# PRU_ICSSG0_PR1_MDIO_V1P7_MDIO register map
Vendor: Texas Instruments
Peripheral module from a debugger description file (folder am243x).
Registers are 32-bit, access not given, reset 0x0 unless marked. A register's access mark holds for its fields unless they carry their own. Offsets are as the file gives them; lines under a group give offsets from that group; [hi:lo] are bit positions; {n}, {i} and the like mark numbered series; 'fields as' and 'values as' point back to an identical list; <NAME> marks a mode.

## PRU_ICSSG0_PR1_MDIO_V1P7_MDIO
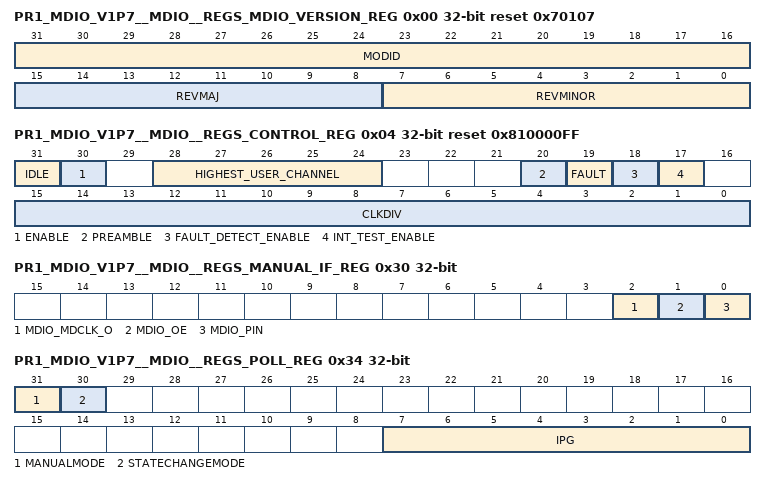
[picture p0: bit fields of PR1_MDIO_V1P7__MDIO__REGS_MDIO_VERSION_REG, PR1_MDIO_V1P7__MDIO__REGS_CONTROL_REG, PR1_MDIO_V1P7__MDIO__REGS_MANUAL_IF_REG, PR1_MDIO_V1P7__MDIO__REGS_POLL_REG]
0x00 PR1_MDIO_V1P7__MDIO__REGS_MDIO_VERSION_REG ro reset 0x70107 — version_reg
  [31:16] MODID — Module ID
  [15:8] REVMAJ — Major revision value
  [7:0] REVMINOR — Minor revision value
0x04 PR1_MDIO_V1P7__MDIO__REGS_CONTROL_REG reset 0x810000FF — control_reg
  [31] IDLE ro — MDIO state machine idle
  [30] ENABLE rw — Enable control
  [28:24] HIGHEST_USER_CHANNEL ro
  [20] PREAMBLE rw — Preamble disable
  [19] FAULT — Fault indicator (access R/W1TC)
  [18] FAULT_DETECT_ENABLE rw
  [17] INT_TEST_ENABLE rw — Interrupt test enable
  [15:0] CLKDIV rw — Clock divider
0x08 PR1_MDIO_V1P7__MDIO__REGS_ALIVE_REG — alive_reg
  [31:0] ALIVE — MDIO alive (access R/W1TC)
0x0C PR1_MDIO_V1P7__MDIO__REGS_LINK_REG ro — link_reg
  [31:0] LINK — MDIO link state
0x10 PR1_MDIO_V1P7__MDIO__REGS_LINK_INT_RAW_REG — link_int_raw_reg
  [1:0] LINKINTRAW — MDIO link change event raw value (access R/W1TC)
0x14 PR1_MDIO_V1P7__MDIO__REGS_LINK_INT_MASKED_REG — link_int_masked_reg
  [1:0] LINKINTMASKED — MDIO link change interrupt masked value (access R/W1TC)
0x18 PR1_MDIO_V1P7__MDIO__REGS_LINK_INT_MASK_SET_REG — link_int_mask_set_reg
  [0] LINKINTMASKSET — MDIO link interrupt mask set (access R/W1TS)
0x1C PR1_MDIO_V1P7__MDIO__REGS_LINK_INT_MASK_CLEAR_REG — link_int_mask_clear_reg
  [0] LINKINTMASKCLR — MDIO link interrupt mask clear (access R/W1TC)
0x20 PR1_MDIO_V1P7__MDIO__REGS_USER_INT_RAW_REG — user_int_raw_reg
  [1:0] USERINTRAW — User interrupt raw (access R/W1TC)
0x24 PR1_MDIO_V1P7__MDIO__REGS_USER_INT_MASKED_REG — user_int_masked_reg
  [1:0] USERINTMASKED — User interrupt masked (access R/W1TC)
0x28 PR1_MDIO_V1P7__MDIO__REGS_USER_INT_MASK_SET_REG — user_int_mask_set_reg
  [1:0] USERINTMASKSET — MDIO user interrupt mask set (access R/W1TS)
0x2C PR1_MDIO_V1P7__MDIO__REGS_USER_INT_MASK_CLEAR_REG — user_int_mask_clear_reg
  [1:0] USERINTMASKCLR — MDIO user interrupt mask clear (access R/W1TC)
0x30 PR1_MDIO_V1P7__MDIO__REGS_MANUAL_IF_REG rw — manual_if_reg
  [2] MDIO_MDCLK_O — MDIO Clock Output
  [1] MDIO_OE — MDIO Output Enable
  [0] MDIO_PIN
0x34 PR1_MDIO_V1P7__MDIO__REGS_POLL_REG rw — poll_reg
  [31] MANUALMODE — MDIO Manual Mode
  [30] STATECHANGEMODE — MDIO State Change Mode
  [7:0] IPG — MDIO IPG
0x38 PR1_MDIO_V1P7__MDIO__REGS_POLL_EN_REG rw reset 0xFFFFFFFF — poll_en_reg
  [31:0] POLL_EN — MDIO Poll Enable
0x3C PR1_MDIO_V1P7__MDIO__REGS_CLAUS45_REG rw
  [31:0] CLAUSE45 — MDIO Clause 45
0x40 PR1_MDIO_V1P7__MDIO__REGS_USER_ADDR0_REG rw — MDIO USER Address 0
  [15:0] USER_ADDR0
0x44 PR1_MDIO_V1P7__MDIO__REGS_USER_ADDR1_REG rw — MDIO USER Address 1
  [15:0] USER_ADDR1
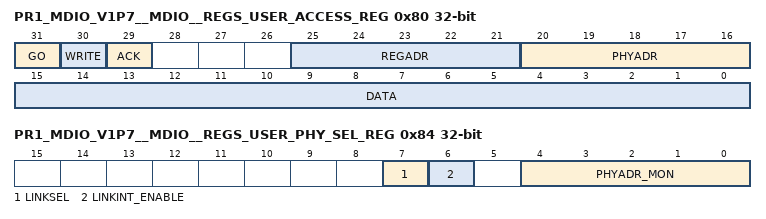
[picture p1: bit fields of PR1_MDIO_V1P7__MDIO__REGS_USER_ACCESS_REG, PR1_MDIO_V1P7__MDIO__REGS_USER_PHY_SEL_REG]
0x80 PR1_MDIO_V1P7__MDIO__REGS_USER_ACCESS_REG — user_access_reg
  [31] GO — Go (access R/W1TS)
  [30] WRITE rw
  [29] ACK rw — Acknowledge
  [25:21] REGADR rw — Register address
  [20:16] PHYADR rw — PHY address
  [15:0] DATA rw — User data
0x84 PR1_MDIO_V1P7__MDIO__REGS_USER_PHY_SEL_REG rw — user_phy_sel_reg
  [7] LINKSEL — Link status determination select
  [6] LINKINT_ENABLE — Link change interrupt enable
  [4:0] PHYADR_MON — PHY address whose link status is monitored
